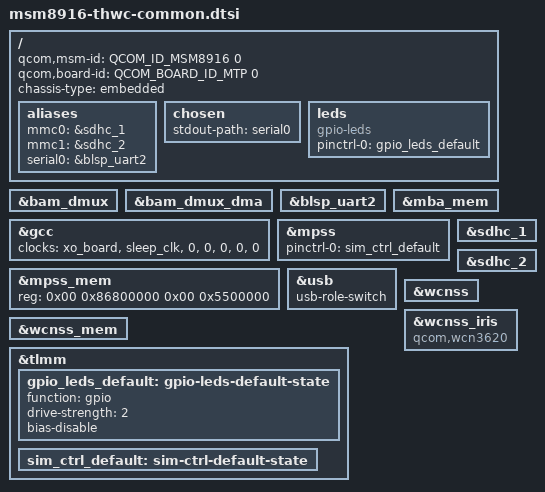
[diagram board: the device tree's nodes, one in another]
// SPDX-License-Identifier: GPL-2.0-only
// A common dtsi for MF32/MF601 series LTE modem dongles.
// https://github.com/CoiaPrant233/msm8916_linux

#include "msm8916-pm8916.dtsi"

#include <dt-bindings/arm/qcom,ids.h>
#include <dt-bindings/gpio/gpio.h>
#include <dt-bindings/leds/common.h>

/ {
	qcom,msm-id = <QCOM_ID_MSM8916 0>;
	qcom,board-id = <QCOM_BOARD_ID_MTP 0>;
	chassis-type = "embedded";

	aliases {
		mmc0 = &sdhc_1; /* eMMC */
		mmc1 = &sdhc_2; /* external SD slot */
		serial0 = &blsp_uart2;
	};

	chosen {
		stdout-path = "serial0";
	};

	leds: leds {
		compatible = "gpio-leds";

		pinctrl-0 = <&gpio_leds_default>;
		pinctrl-names = "default";

		/* LEDs are board-specific */
	};
};

&bam_dmux {
	status = "okay";
};

&bam_dmux_dma {
	status = "okay";
};

&blsp_uart2 {
	status = "okay";
};

/* Remove &dsi_phy0 from clocks to make sure that gcc probes with display disabled */
&gcc {
	clocks = <&xo_board>, <&sleep_clk>, <0>, <0>, <0>, <0>, <0>;
};

&mba_mem {
	status = "okay";
};

&mpss {
	pinctrl-0 = <&sim_ctrl_default>;
	pinctrl-names = "default";

	status = "okay";
};

&mpss_mem {
	reg = <0x00 0x86800000 0x00 0x5500000>;
	status = "okay";
};

&sdhc_1 {
	status = "okay";
};

&sdhc_2 {
	status = "okay";
};

&usb {
	usb-role-switch;

	status = "okay";
};
/*
&venus {
	status = "okay";
};

&venus_mem {
	status = "okay";
};
*/
&wcnss {
	status = "okay";
};

&wcnss_iris {
	compatible = "qcom,wcn3620";
};

&wcnss_mem {
	status = "okay";
};

&tlmm {
	gpio_leds_default: gpio-leds-default-state {
		function = "gpio";
		drive-strength = <2>;
		/* "pins" are board-specific */
		bias-disable;
	};

	/* This selects the external SIM card slot by default */
	sim_ctrl_default: sim-ctrl-default-state {
		/* "pins" are board-specific */
	};
};
